VERSION ""

NS_ :

BS_:

BU_:

BO_ 2566852904 Dspl: 2 Vector__XXX
 SG_ swtStatus : 8|2@1+ (1,0) [0|3] "" Vector__XXX
 SG_ anValue : 0|8@1+ (1,0) [0|100] "%" Vector__XXX

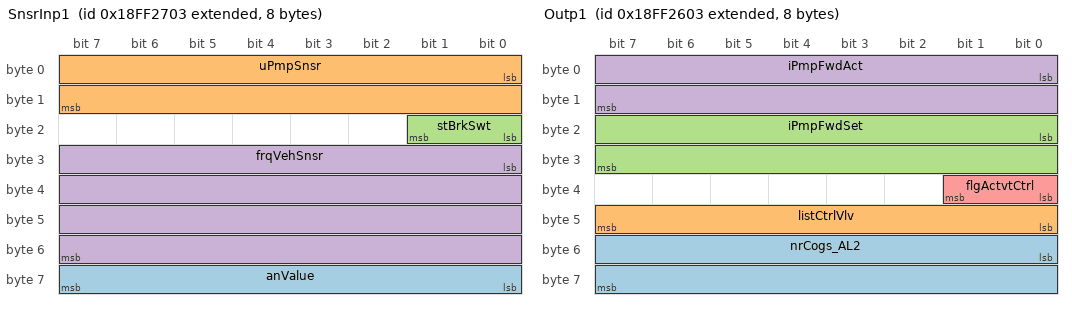
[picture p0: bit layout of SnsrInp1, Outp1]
BO_ 2566858499 SnsrInp1: 8 Vector__XXX
 SG_ anValue : 56|8@1+ (1,0) [0|100] "%" Vector__XXX
 SG_ uPmpSnsr : 0|16@1+ (1,0) [0|65535] "mV" Vector__XXX
 SG_ stBrkSwt : 16|2@1+ (1,0) [0|3] "" Vector__XXX
 SG_ frqVehSnsr : 24|32@1+ (1,0) [0|4294967295] "Hz" Vector__XXX

BO_ 2566858243 Outp1: 8 Vector__XXX
 SG_ nrCogs_AL2 : 48|16@1+ (1,0) [0|65535] "" Vector__XXX
 SG_ listCtrlVlv : 40|8@1+ (1,0) [0|255] "" Vector__XXX
 SG_ iPmpFwdSet : 16|16@1+ (1,0) [0|4090] "mA" Vector__XXX
 SG_ iPmpFwdAct : 0|16@1+ (1,0) [0|4090] "mA" Vector__XXX
 SG_ flgActvtCtrl : 32|2@1+ (1,0) [0|3] "" Vector__XXX

CM_ SG_ 2566852904 swtStatus "Switch value for the test purposes";
CM_ SG_ 2566852904 anValue "Analog value for the test purposes";
CM_ SG_ 2566858499 anValue "Analog value for the test purposes";
CM_ SG_ 2566858499 uPmpSnsr "Voltage of the pump pressure - channel A";
CM_ SG_ 2566858499 stBrkSwt "Status of the input switch";
CM_ SG_ 2566858499 frqVehSnsr "Vehicle speed measured with the speed sensor";
CM_ SG_ 2566858243 nrCogs_AL2 "No. of cogs from DID C003";
CM_ SG_ 2566858243 listCtrlVlv "List parameter DID C002";
CM_ SG_ 2566858243 iPmpFwdSet "Current of the pump forward proportional valve";
CM_ SG_ 2566858243 iPmpFwdAct "Current of the pump forward proportional valve";
CM_ SG_ 2566858243 flgActvtCtrl "Status flag for the activation of the control valve (digital)";
BA_DEF_ SG_  "SigType" ENUM  "Default","Range","RangeSigned","ASCII","Discrete","Control","ReferencePGN","DTC","StringDelimiter","StringLength","StringLengthControl";
BA_DEF_ BO_  "GenMsgRequestable" INT 0 1;
BA_DEF_ BO_  "GenMsgSendType" ENUM  "cyclic","NotUsed","NotUsed","NotUsed","NotUsed","NotUsed","NotUsed","IfActive","noMsgSendType";
BA_DEF_ BO_  "VFrameFormat" ENUM  "StandardCAN","ExtendedCAN","reserved","J1939PG";
BA_DEF_ BO_  "GenMsgCycleTime" INT 0 3600000;
BA_DEF_ BU_  "NmStationAddress" INT 0 255;
BA_DEF_  "BusType" STRING ;
BA_DEF_  "ProtocolType" STRING ;
BA_DEF_DEF_  "SigType" "Default";
BA_DEF_DEF_  "GenMsgRequestable" 1;
BA_DEF_DEF_  "GenMsgSendType" "noMsgSendType";
BA_DEF_DEF_  "VFrameFormat" "StandardCAN";
BA_DEF_DEF_  "GenMsgCycleTime" 0;
BA_DEF_DEF_  "NmStationAddress" 254;
BA_DEF_DEF_  "BusType" "";
BA_DEF_DEF_  "ProtocolType" "";
BA_ "ProtocolType" "J1939";
BA_ "BusType" "CAN";
BA_ "VFrameFormat" BO_ 2566852904 3;
BA_ "VFrameFormat" BO_ 2566858499 3;
BA_ "VFrameFormat" BO_ 2566858243 3;
